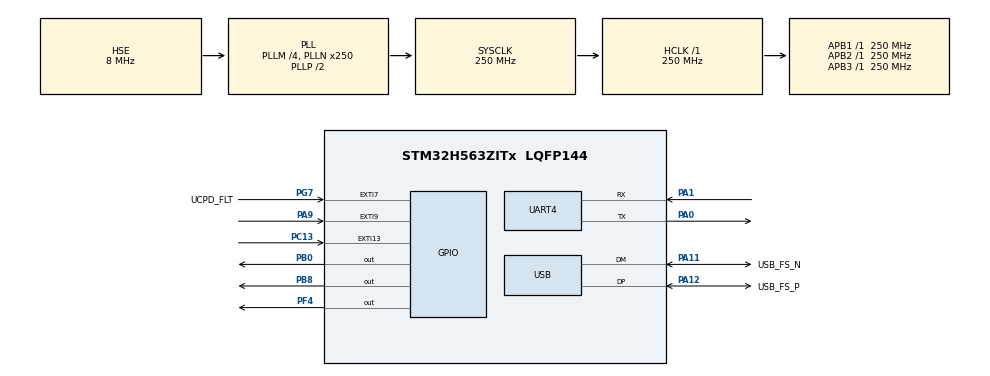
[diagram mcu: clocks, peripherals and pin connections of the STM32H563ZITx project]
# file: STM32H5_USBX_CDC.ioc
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BOOTPATH.BootPathName=LEGACY
BOOTPATH.UserSelectedBootPath=LEGACY
CORTEX_M33_NS.userName=CORTEX_M33
GPDMA1.DIRECTION_GPDMACH0=DMA_MEMORY_TO_PERIPH
GPDMA1.IPHANDLE_GPDMACH0-SIMPLEREQUEST_GPDMACH0=__NULL
GPDMA1.REQUEST_GPDMACH0=GPDMA1_REQUEST_UART4_TX
GPDMA1.SRCINC_GPDMACH0=DMA_SINC_INCREMENTED
Mcu.Family=STM32H5
Mcu.Name=STM32H563ZITx
Mcu.Package=LQFP144
NUCLEO-H563ZI.BUTTON=1
NUCLEO-H563ZI.LD1=true
NUCLEO-H563ZI.LD2=true
NUCLEO-H563ZI.LD3=true
NUCLEO-H563ZI.VCP=false
NVIC.EXTI13_IRQn=true\:0\:0\:false\:false\:true\:false\:true\:true
NVIC.GPDMA1_Channel0_IRQn=true\:0\:0\:false\:false\:true\:false\:true\:true
NVIC.PriorityGroup=NVIC_PRIORITYGROUP_4
NVIC.TIM6_IRQn=true\:0\:0\:false\:false\:true\:true\:true\:true
NVIC.USB_DRD_FS_IRQn=true\:0\:0\:false\:false\:true\:true\:true\:true
PA0.Mode=Asynchronous
PA0.Signal=UART4_TX
PA1.Mode=Asynchronous
PA1.Signal=UART4_RX
PA11.GPIO_Label=USB_FS_N
PA11.Mode=Device
PA11.Signal=USB_DM
PA12.GPIO_Label=USB_FS_P
PA12.Mode=Device
PA12.Signal=USB_DP
PA13(JTMS/SWDIO).GPIO_Label=SWDIO
PA13(JTMS/SWDIO).Mode=Serial_Wire
PA13(JTMS/SWDIO).Signal=DEBUG_JTMS-SWDIO
PA14(JTCK/SWCLK).GPIO_Label=SWCLK
PA14(JTCK/SWCLK).Mode=Serial_Wire
PA14(JTCK/SWCLK).Signal=DEBUG_JTCK-SWCLK
PA9.Signal=GPXTI9
PB0.Signal=GPIO_Output
PB8.GPIO_Speed=GPIO_SPEED_FREQ_HIGH
PB8.Signal=GPIO_Output
PC13.Signal=GPXTI13
PC14-OSC32_IN(OSC32_IN).Mode=LSE-External-Oscillator
PC14-OSC32_IN(OSC32_IN).Signal=RCC_OSC32_IN
PC15-OSC32_OUT(OSC32_OUT).Mode=LSE-External-Oscillator
PC15-OSC32_OUT(OSC32_OUT).Signal=RCC_OSC32_OUT
PF4.Signal=GPIO_Output
PG7.GPIO_Label=UCPD_FLT
PG7.Signal=GPXTI7
PH0-OSC_IN(PH0).GPIO_Label=STLK_MCO
PH0-OSC_IN(PH0).Mode=HSE-External-Clock-Source
PH0-OSC_IN(PH0).Signal=RCC_OSC_IN
ProjectManager.HeapSize=0x600
ProjectManager.StackSize=0x800
ProjectManager.TargetToolchain=STM32CubeIDE
RCC.ADCFreq_Value=250000000
RCC.AHBFreq_Value=250000000
RCC.APB1Freq_Value=250000000
RCC.APB1TimFreq_Value=250000000
RCC.APB2Freq_Value=250000000
RCC.APB2TimFreq_Value=250000000
RCC.APB3Freq_Value=250000000
RCC.CSI_VALUE=4000000
RCC.CortexFreq_Value=250000000
RCC.EPOD_VALUE=8000000
RCC.HCLKFreq_Value=250000000
RCC.HSE_VALUE=8000000
RCC.HSI48_VALUE=48000000
RCC.HSIDiv=RCC_HSI_DIV1
RCC.HSI_VALUE=64000000
RCC.LSIRC_VALUE=32000
RCC.PLLM=4
RCC.PLLN=250
RCC.PLLSourceVirtual=RCC_PLL1_SOURCE_HSE
RCC.SYSCLKFreq_VALUE=250000000
RCC.SYSCLKSource=RCC_SYSCLKSOURCE_PLLCLK
RCC.USBFreq_Value=48000000
RCC.VCOOutputFreq_Value=500000000
TIM6.PeriodNoDither=1
TIM6.Prescaler=31249
USB.VirtualMode=Device_Only
USBX.BSP.number=1
USBX.Core_System=1
USBX.MAX_POWER_IN_MILLI_AMPER=0
USBX.REG_USBX_DEVICE_CON_CK=1
USBX.USBD_CDCACM_EPINCMD_ADDR=2
USBX.USBD_CDCACM_EPIN_ADDR=1
USBX.USBD_CDCACM_EPOUT_ADDR=3
USBX.USBD_PID=22336
USBX.USBD_PRODUCT_STRING=STM32 Virtual ComPort
USBX.USBD_SERIAL_NUMBER=CDC_ACM001
USBX.USBX_DEVICE_SYS_SIZE=4*1024
USBX.UX_DEVICE_APP_MEM_POOL_SIZE_STANDALONE=8*1024
USBX.UX_DEVICE_CDC_ACM=1
USBX.UX_DEVICE_CLASS_CDC_ACM_WRITE_AUTO_ZLP=1
USBX.UX_Device_Controller=1
USBX.UX_Device_CoreStack=1
USBX.UX_SLAVE_REQUEST_DATA_MAX_LENGTH=512
USBX0.BSP.STBoard=false
USBX0.BSP.api=Unknown
USBX0.BSP.instance=USB
USBX0.BSP.ip=USB
USBX0.BSP.mode=Device_Only
USBX0.BSP.name=USB_Device
USBX0.BSP.solution=USB
VP_BOOTPATH_VS_BOOTPATH.Mode=BP_Activate
VP_CORTEX_M33_NS_VS_Hclk.Mode=Hclk_Mode
VP_GPDMA1_VS_GPDMACH0.Mode=SIMPLEREQUEST_GPDMACH0
VP_MEMORYMAP_VS_MEMORYMAP.Mode=CurAppReg
VP_NUCLEO-H563ZI_VS_BSP_COMMON.Mode=COMMON
VP_PWR_VS_DBSignals.Mode=DisableDeadBatterySignals
VP_PWR_VS_LPOM.Mode=PowerOptimisation
VP_PWR_VS_SECSignals.Mode=Security/Privilege
VP_TIM6_VS_ClockSourceINT.Mode=Enable_Timer
VP_USBX_Core_System.Mode=Core_System
VP_USBX_UX\ Device\ CDC\ ACM\ Class_FS.Mode=UX_Device_class_CDC_ACM_FS
VP_USBX_UX\ Device\ Controller_FS.Mode=UX_Device_Controller_FS
VP_USBX_UX\ Device\ CoreStack_FS.Mode=UX_Device_CoreStack_FS
board=NUCLEO-H563ZI

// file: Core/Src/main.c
/* USER CODE BEGIN Header */
/**
  ******************************************************************************
  * @file           : main.c
  * @brief          : Main program body
  ******************************************************************************
  * @attention
  *
  * Copyright (c) 2024 STMicroelectronics.
  * All rights reserved.
  *
  * This software is licensed under terms that can be found in the LICENSE file
  * in the root directory of this software component.
  * If no LICENSE file comes with this software, it is provided AS-IS.
  *
  ******************************************************************************
  */
/* USER CODE END Header */
#include "main.h"
#include "app_usbx_device.h"

/* USER CODE BEGIN Includes */
#include <stdio.h>
/* USER CODE END Includes */

TIM_HandleTypeDef htim6;

UART_HandleTypeDef huart4;
DMA_HandleTypeDef handle_GPDMA1_Channel0;

PCD_HandleTypeDef hpcd_USB_DRD_FS;

void SystemClock_Config(void);
static void MX_GPIO_Init(void);
static void MX_GPDMA1_Init(void);
static void MX_TIM6_Init(void);
static void MX_UART4_Init(void);

/* USER CODE BEGIN 0 */
int _write(int file, char *ptr, int len)
{
	CDC_Transmit_FS((char*)ptr, len);

	return len;
}

/* USER CODE END 0 */

int main(void)
{

  /* MCU Configuration--------------------------------------------------------*/

  /* Reset of all peripherals, Initializes the Flash interface and the Systick. */
  HAL_Init();

  /* Configure the system clock */
  SystemClock_Config();

  /* Initialize all configured peripherals */
  MX_GPIO_Init();
  MX_GPDMA1_Init();
  MX_TIM6_Init();
  MX_UART4_Init();
  MX_USBX_Device_Init();
  /* USER CODE BEGIN 2 */
  HAL_TIM_Base_Start_IT(&htim6);
  /* USER CODE END 2 */

  /* Initialize leds */
  BSP_LED_Init(LED_GREEN);
  BSP_LED_Init(LED_YELLOW);
  BSP_LED_Init(LED_RED);

  /* Initialize USER push-button, will be used to trigger an interrupt each time it's pressed.*/
  BSP_PB_Init(BUTTON_USER, BUTTON_MODE_EXTI);

  /* Infinite loop */
  /* USER CODE BEGIN WHILE */
  while (1)
  {
	  MX_USBX_Device_Process(NULL);
    /* USER CODE END WHILE */

  }
}

void SystemClock_Config(void)
{
  RCC_OscInitTypeDef RCC_OscInitStruct = {0};
  RCC_ClkInitTypeDef RCC_ClkInitStruct = {0};

  /** Configure the main internal regulator output voltage
  */
  __HAL_PWR_VOLTAGESCALING_CONFIG(PWR_REGULATOR_VOLTAGE_SCALE0);

  while(!__HAL_PWR_GET_FLAG(PWR_FLAG_VOSRDY)) {}

  /** Initializes the RCC Oscillators according to the specified parameters
  * in the RCC_OscInitTypeDef structure.
  */
  RCC_OscInitStruct.OscillatorType = RCC_OSCILLATORTYPE_HSI48|RCC_OSCILLATORTYPE_HSE;
  RCC_OscInitStruct.HSEState = RCC_HSE_BYPASS;
  RCC_OscInitStruct.HSI48State = RCC_HSI48_ON;
  RCC_OscInitStruct.PLL.PLLState = RCC_PLL_ON;
  RCC_OscInitStruct.PLL.PLLSource = RCC_PLL1_SOURCE_HSE;
  RCC_OscInitStruct.PLL.PLLM = 4;
  RCC_OscInitStruct.PLL.PLLN = 250;
  RCC_OscInitStruct.PLL.PLLP = 2;
  RCC_OscInitStruct.PLL.PLLQ = 2;
  RCC_OscInitStruct.PLL.PLLR = 2;
  RCC_OscInitStruct.PLL.PLLRGE = RCC_PLL1_VCIRANGE_1;
  RCC_OscInitStruct.PLL.PLLVCOSEL = RCC_PLL1_VCORANGE_WIDE;
  RCC_OscInitStruct.PLL.PLLFRACN = 0;
  if (HAL_RCC_OscConfig(&RCC_OscInitStruct) != HAL_OK)
  {
    Error_Handler();
  }

  /** Initializes the CPU, AHB and APB buses clocks
  */
  RCC_ClkInitStruct.ClockType = RCC_CLOCKTYPE_HCLK|RCC_CLOCKTYPE_SYSCLK
                              |RCC_CLOCKTYPE_PCLK1|RCC_CLOCKTYPE_PCLK2
                              |RCC_CLOCKTYPE_PCLK3;
  RCC_ClkInitStruct.SYSCLKSource = RCC_SYSCLKSOURCE_PLLCLK;
  RCC_ClkInitStruct.AHBCLKDivider = RCC_SYSCLK_DIV1;
  RCC_ClkInitStruct.APB1CLKDivider = RCC_HCLK_DIV1;
  RCC_ClkInitStruct.APB2CLKDivider = RCC_HCLK_DIV1;
  RCC_ClkInitStruct.APB3CLKDivider = RCC_HCLK_DIV1;

  if (HAL_RCC_ClockConfig(&RCC_ClkInitStruct, FLASH_LATENCY_5) != HAL_OK)
  {
    Error_Handler();
  }
}

static void MX_GPDMA1_Init(void)
{

  /* Peripheral clock enable */
  __HAL_RCC_GPDMA1_CLK_ENABLE();

  /* GPDMA1 interrupt Init */
    HAL_NVIC_SetPriority(GPDMA1_Channel0_IRQn, 0, 0);
    HAL_NVIC_EnableIRQ(GPDMA1_Channel0_IRQn);

}

static void MX_TIM6_Init(void)
{

  TIM_MasterConfigTypeDef sMasterConfig = {0};

  htim6.Instance = TIM6;
  htim6.Init.Prescaler = 31249;
  htim6.Init.CounterMode = TIM_COUNTERMODE_UP;
  htim6.Init.Period = 1;
  htim6.Init.AutoReloadPreload = TIM_AUTORELOAD_PRELOAD_DISABLE;
  if (HAL_TIM_Base_Init(&htim6) != HAL_OK)
  {
    Error_Handler();
  }
  sMasterConfig.MasterOutputTrigger = TIM_TRGO_RESET;
  sMasterConfig.MasterSlaveMode = TIM_MASTERSLAVEMODE_DISABLE;
  if (HAL_TIMEx_MasterConfigSynchronization(&htim6, &sMasterConfig) != HAL_OK)
  {
    Error_Handler();
  }

}

static void MX_UART4_Init(void)
{

  huart4.Instance = UART4;
  huart4.Init.BaudRate = 115200;
  huart4.Init.WordLength = UART_WORDLENGTH_8B;
  huart4.Init.StopBits = UART_STOPBITS_1;
  huart4.Init.Parity = UART_PARITY_NONE;
  huart4.Init.Mode = UART_MODE_TX_RX;
  huart4.Init.HwFlowCtl = UART_HWCONTROL_NONE;
  huart4.Init.OverSampling = UART_OVERSAMPLING_16;
  huart4.Init.OneBitSampling = UART_ONE_BIT_SAMPLE_DISABLE;
  huart4.Init.ClockPrescaler = UART_PRESCALER_DIV1;
  huart4.AdvancedInit.AdvFeatureInit = UART_ADVFEATURE_NO_INIT;
  if (HAL_UART_Init(&huart4) != HAL_OK)
  {
    Error_Handler();
  }
  if (HAL_UARTEx_SetTxFifoThreshold(&huart4, UART_TXFIFO_THRESHOLD_1_8) != HAL_OK)
  {
    Error_Handler();
  }
  if (HAL_UARTEx_SetRxFifoThreshold(&huart4, UART_RXFIFO_THRESHOLD_1_8) != HAL_OK)
  {
    Error_Handler();
  }
  if (HAL_UARTEx_DisableFifoMode(&huart4) != HAL_OK)
  {
    Error_Handler();
  }

}

void MX_USB_PCD_Init(void)
{

  hpcd_USB_DRD_FS.Instance = USB_DRD_FS;
  hpcd_USB_DRD_FS.Init.dev_endpoints = 8;
  hpcd_USB_DRD_FS.Init.speed = USBD_FS_SPEED;
  hpcd_USB_DRD_FS.Init.phy_itface = PCD_PHY_EMBEDDED;
  hpcd_USB_DRD_FS.Init.Sof_enable = DISABLE;
  hpcd_USB_DRD_FS.Init.low_power_enable = DISABLE;
  hpcd_USB_DRD_FS.Init.lpm_enable = DISABLE;
  hpcd_USB_DRD_FS.Init.battery_charging_enable = DISABLE;
  hpcd_USB_DRD_FS.Init.vbus_sensing_enable = DISABLE;
  hpcd_USB_DRD_FS.Init.bulk_doublebuffer_enable = DISABLE;
  hpcd_USB_DRD_FS.Init.iso_singlebuffer_enable = DISABLE;
  if (HAL_PCD_Init(&hpcd_USB_DRD_FS) != HAL_OK)
  {
    Error_Handler();
  }

}

static void MX_GPIO_Init(void)
{
  GPIO_InitTypeDef GPIO_InitStruct = {0};

  /* GPIO Ports Clock Enable */
  __HAL_RCC_GPIOC_CLK_ENABLE();
  __HAL_RCC_GPIOH_CLK_ENABLE();
  __HAL_RCC_GPIOA_CLK_ENABLE();
  __HAL_RCC_GPIOG_CLK_ENABLE();
  __HAL_RCC_GPIOB_CLK_ENABLE();

  /*Configure GPIO pin Output Level */
  HAL_GPIO_WritePin(GPIOB, GPIO_PIN_8, GPIO_PIN_RESET);

  /*Configure GPIO pin : UCPD_FLT_Pin */
  GPIO_InitStruct.Pin = UCPD_FLT_Pin;
  GPIO_InitStruct.Mode = GPIO_MODE_IT_RISING;
  GPIO_InitStruct.Pull = GPIO_NOPULL;
  HAL_GPIO_Init(UCPD_FLT_GPIO_Port, &GPIO_InitStruct);

  /*Configure GPIO pin : PA9 */
  GPIO_InitStruct.Pin = GPIO_PIN_9;
  GPIO_InitStruct.Mode = GPIO_MODE_IT_RISING;
  GPIO_InitStruct.Pull = GPIO_NOPULL;
  HAL_GPIO_Init(GPIOA, &GPIO_InitStruct);

  /*Configure GPIO pin : PB8 */
  GPIO_InitStruct.Pin = GPIO_PIN_8;
  GPIO_InitStruct.Mode = GPIO_MODE_OUTPUT_PP;
  GPIO_InitStruct.Pull = GPIO_NOPULL;
  GPIO_InitStruct.Speed = GPIO_SPEED_FREQ_HIGH;
  HAL_GPIO_Init(GPIOB, &GPIO_InitStruct);

}

/* USER CODE BEGIN 4 */
/**
  * @brief  Period elapsed callback in non-blocking mode
  * @param  htim TIM handle
  * @retval None
  */
void HAL_TIM_PeriodElapsedCallback(TIM_HandleTypeDef *htim)
{
  printf("ABCDEFG\n");
}
/* USER CODE END 4 */

void Error_Handler(void)
{
  __disable_irq();
  while (1)
  {
  }
}
